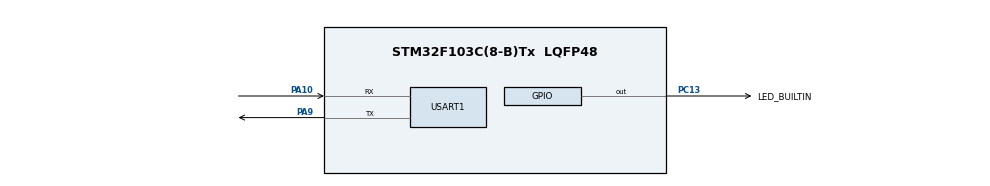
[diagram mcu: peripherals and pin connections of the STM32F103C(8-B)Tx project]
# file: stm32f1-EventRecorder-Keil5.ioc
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FREERTOS.Tasks01=defaultTask,0,128,StartDefaultTask,Default,NULL
Mcu.Family=STM32F1
Mcu.Name=STM32F103C(8-B)Tx
Mcu.Package=LQFP48
NVIC.PriorityGroup=NVIC_PRIORITYGROUP_4
NVIC.TIM4_IRQn=true\:0\:0\:false\:false\:true\:false\:false
NVIC.TimeBase=TIM4_IRQn
NVIC.TimeBaseIP=TIM4
NVIC.USART1_IRQn=true\:5\:0\:false\:false\:true\:true\:true
PA10.Mode=Asynchronous
PA10.Signal=USART1_RX
PA13.Mode=Serial_Wire
PA13.Signal=SYS_JTMS-SWDIO
PA14.Mode=Serial_Wire
PA14.Signal=SYS_JTCK-SWCLK
PA9.Mode=Asynchronous
PA9.Signal=USART1_TX
PC13-TAMPER-RTC.GPIO_Label=LED_BUILTIN
PC13-TAMPER-RTC.Signal=GPIO_Output
PD0-OSC_IN.Mode=HSE-External-Oscillator
PD0-OSC_IN.Signal=RCC_OSC_IN
PD1-OSC_OUT.Mode=HSE-External-Oscillator
PD1-OSC_OUT.Signal=RCC_OSC_OUT
ProjectManager.HeapSize=0x200
ProjectManager.StackSize=0x400
ProjectManager.TargetToolchain=MDK-ARM V5
RCC.AHBFreq_Value=16000000
RCC.APB1Freq_Value=16000000
RCC.APB1TimFreq_Value=16000000
RCC.APB2Freq_Value=16000000
RCC.APB2TimFreq_Value=16000000
RCC.HCLKFreq_Value=16000000
RCC.PLLSourceVirtual=RCC_PLLSOURCE_HSE
RCC.SYSCLKFreq_VALUE=16000000
RCC.SYSCLKSource=RCC_SYSCLKSOURCE_PLLCLK
RCC.USBFreq_Value=16000000
USART1.VirtualMode=VM_ASYNC
VP_FREERTOS_VS_ENABLE.Mode=Enabled
VP_SYS_VS_tim4.Mode=TIM4
board=custom

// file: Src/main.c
/* USER CODE BEGIN Header */
/**
  ******************************************************************************
  * @file           : main.c
  * @brief          : Main program body
  ******************************************************************************
  * This notice applies to any and all portions of this file
  * that are not between comment pairs USER CODE BEGIN and
  * USER CODE END. Other portions of this file, whether
  * inserted by the user or by software development tools
  * are owned by their respective copyright owners.
  *
  * Copyright (c) 2019 STMicroelectronics International N.V.
  * All rights reserved.
  *
  * Redistribution and use in source and binary forms, with or without
  * modification, are permitted, provided that the following conditions are met:
  *
  * 1. Redistribution of source code must retain the above copyright notice,
  *    this list of conditions and the following disclaimer.
  * 2. Redistributions in binary form must reproduce the above copyright notice,
  *    this list of conditions and the following disclaimer in the documentation
  *    and/or other materials provided with the distribution.
  * 3. Neither the name of STMicroelectronics nor the names of other
  *    contributors to this software may be used to endorse or promote products
  *    derived from this software without specific written permission.
  * 4. This software, including modifications and/or derivative works of this
  *    software, must execute solely and exclusively on microcontroller or
  *    microprocessor devices manufactured by or for STMicroelectronics.
  * 5. Redistribution and use of this software other than as permitted under
  *    this license is void and will automatically terminate your rights under
  *    this license.
  *
  * THIS SOFTWARE IS PROVIDED BY STMICROELECTRONICS AND CONTRIBUTORS "AS IS"
  * AND ANY EXPRESS, IMPLIED OR STATUTORY WARRANTIES, INCLUDING, BUT NOT
  * LIMITED TO, THE IMPLIED WARRANTIES OF MERCHANTABILITY, FITNESS FOR A
  * PARTICULAR PURPOSE AND NON-INFRINGEMENT OF THIRD PARTY INTELLECTUAL PROPERTY
  * RIGHTS ARE DISCLAIMED TO THE FULLEST EXTENT PERMITTED BY LAW. IN NO EVENT
  * SHALL STMICROELECTRONICS OR CONTRIBUTORS BE LIABLE FOR ANY DIRECT, INDIRECT,
  * INCIDENTAL, SPECIAL, EXEMPLARY, OR CONSEQUENTIAL DAMAGES (INCLUDING, BUT NOT
  * LIMITED TO, PROCUREMENT OF SUBSTITUTE GOODS OR SERVICES; LOSS OF USE, DATA,
  * OR PROFITS; OR BUSINESS INTERRUPTION) HOWEVER CAUSED AND ON ANY THEORY OF
  * LIABILITY, WHETHER IN CONTRACT, STRICT LIABILITY, OR TORT (INCLUDING
  * NEGLIGENCE OR OTHERWISE) ARISING IN ANY WAY OUT OF THE USE OF THIS SOFTWARE,
  * EVEN IF ADVISED OF THE POSSIBILITY OF SUCH DAMAGE.
  *
  ******************************************************************************
  */
/* USER CODE END Header */

#include "main.h"
#include "cmsis_os.h"
#include "usart.h"
#include "gpio.h"

void SystemClock_Config(void);
void MX_FREERTOS_Init(void);

int main(void)
{

  /* MCU Configuration--------------------------------------------------------*/

  /* Reset of all peripherals, Initializes the Flash interface and the Systick. */
  HAL_Init();

  /* Configure the system clock */
  SystemClock_Config();

  /* Initialize all configured peripherals */
  MX_GPIO_Init();
  MX_USART1_UART_Init();

  /* Call init function for freertos objects (in freertos.c) */
  MX_FREERTOS_Init();

  /* Start scheduler */
  osKernelStart();

  /* We should never get here as control is now taken by the scheduler */

  /* Infinite loop */
  while (1)
  {

  }
}

void SystemClock_Config(void)
{
  LL_FLASH_SetLatency(LL_FLASH_LATENCY_0);

  if(LL_FLASH_GetLatency() != LL_FLASH_LATENCY_0)
  {
    Error_Handler();
  }
  LL_RCC_HSE_Enable();

   /* Wait till HSE is ready */
  while(LL_RCC_HSE_IsReady() != 1)
  {

  }
  LL_RCC_PLL_ConfigDomain_SYS(LL_RCC_PLLSOURCE_HSE_DIV_1, LL_RCC_PLL_MUL_2);
  LL_RCC_PLL_Enable();

   /* Wait till PLL is ready */
  while(LL_RCC_PLL_IsReady() != 1)
  {

  }
  LL_RCC_SetAHBPrescaler(LL_RCC_SYSCLK_DIV_1);
  LL_RCC_SetAPB1Prescaler(LL_RCC_APB1_DIV_1);
  LL_RCC_SetAPB2Prescaler(LL_RCC_APB2_DIV_1);
  LL_RCC_SetSysClkSource(LL_RCC_SYS_CLKSOURCE_PLL);

   /* Wait till System clock is ready */
  while(LL_RCC_GetSysClkSource() != LL_RCC_SYS_CLKSOURCE_STATUS_PLL)
  {

  }
  LL_Init1msTick(16000000);
  LL_SYSTICK_SetClkSource(LL_SYSTICK_CLKSOURCE_HCLK);
  LL_SetSystemCoreClock(16000000);
}

void HAL_TIM_PeriodElapsedCallback(TIM_HandleTypeDef *htim)
{
  if (htim->Instance == TIM4) {
    HAL_IncTick();
  }
}

void Error_Handler(void)
{
}

/************************ (C) COPYRIGHT STMicroelectronics *****END OF FILE****/

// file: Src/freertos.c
/* USER CODE BEGIN Header */
/**
  ******************************************************************************
  * File Name          : freertos.c
  * Description        : Code for freertos applications
  ******************************************************************************
  * This notice applies to any and all portions of this file
  * that are not between comment pairs USER CODE BEGIN and
  * USER CODE END. Other portions of this file, whether
  * inserted by the user or by software development tools
  * are owned by their respective copyright owners.
  *
  * Copyright (c) 2019 STMicroelectronics International N.V.
  * All rights reserved.
  *
  * Redistribution and use in source and binary forms, with or without
  * modification, are permitted, provided that the following conditions are met:
  *
  * 1. Redistribution of source code must retain the above copyright notice,
  *    this list of conditions and the following disclaimer.
  * 2. Redistributions in binary form must reproduce the above copyright notice,
  *    this list of conditions and the following disclaimer in the documentation
  *    and/or other materials provided with the distribution.
  * 3. Neither the name of STMicroelectronics nor the names of other
  *    contributors to this software may be used to endorse or promote products
  *    derived from this software without specific written permission.
  * 4. This software, including modifications and/or derivative works of this
  *    software, must execute solely and exclusively on microcontroller or
  *    microprocessor devices manufactured by or for STMicroelectronics.
  * 5. Redistribution and use of this software other than as permitted under
  *    this license is void and will automatically terminate your rights under
  *    this license.
  *
  * THIS SOFTWARE IS PROVIDED BY STMICROELECTRONICS AND CONTRIBUTORS "AS IS"
  * AND ANY EXPRESS, IMPLIED OR STATUTORY WARRANTIES, INCLUDING, BUT NOT
  * LIMITED TO, THE IMPLIED WARRANTIES OF MERCHANTABILITY, FITNESS FOR A
  * PARTICULAR PURPOSE AND NON-INFRINGEMENT OF THIRD PARTY INTELLECTUAL PROPERTY
  * RIGHTS ARE DISCLAIMED TO THE FULLEST EXTENT PERMITTED BY LAW. IN NO EVENT
  * SHALL STMICROELECTRONICS OR CONTRIBUTORS BE LIABLE FOR ANY DIRECT, INDIRECT,
  * INCIDENTAL, SPECIAL, EXEMPLARY, OR CONSEQUENTIAL DAMAGES (INCLUDING, BUT NOT
  * LIMITED TO, PROCUREMENT OF SUBSTITUTE GOODS OR SERVICES; LOSS OF USE, DATA,
  * OR PROFITS; OR BUSINESS INTERRUPTION) HOWEVER CAUSED AND ON ANY THEORY OF
  * LIABILITY, WHETHER IN CONTRACT, STRICT LIABILITY, OR TORT (INCLUDING
  * NEGLIGENCE OR OTHERWISE) ARISING IN ANY WAY OUT OF THE USE OF THIS SOFTWARE,
  * EVEN IF ADVISED OF THE POSSIBILITY OF SUCH DAMAGE.
  *
  ******************************************************************************
  */
/* USER CODE END Header */

#include "FreeRTOS.h"
#include "task.h"
#include "main.h"
#include "cmsis_os.h"

/* USER CODE BEGIN Includes */
#include "EventRecorder.h"

/* USER CODE END Includes */

osThreadId defaultTaskHandle;

void StartDefaultTask(void const * argument);

void MX_FREERTOS_Init(void); /* (MISRA C 2004 rule 8.1) */

void MX_FREERTOS_Init(void) {

  /* Create the thread(s) */
  /* definition and creation of defaultTask */
  osThreadDef(defaultTask, StartDefaultTask, osPriorityNormal, 0, 128);
  defaultTaskHandle = osThreadCreate(osThread(defaultTask), NULL);

}

void StartDefaultTask(void const * argument)
{

  /* USER CODE BEGIN StartDefaultTask */
  EventRecorderInitialize(EventRecordAll, 1U);
  EventRecorderStart();
  /* Infinite loop */
  for(;;)
  {
    EventStartA(0); /* start time loss measurement */
    LL_GPIO_TogglePin(LED_BUILTIN_GPIO_Port, LED_BUILTIN_Pin);
    HAL_Delay(1000);
    EventStopA(0); /* stop time loss measurement */
    printf("Time Loss measurement over...\r\n");
    osDelay(1000);

  }
  /* USER CODE END StartDefaultTask */
}

/************************ (C) COPYRIGHT STMicroelectronics *****END OF FILE****/
